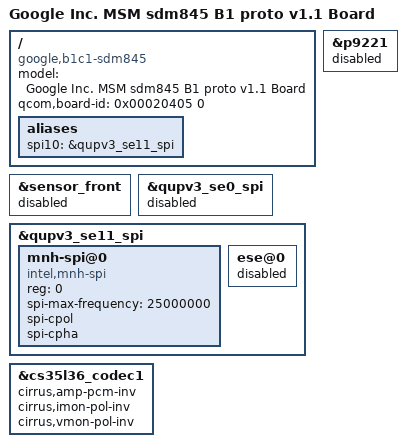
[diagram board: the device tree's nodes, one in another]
/* Copyright (c) 2017, The Linux Foundation. All rights reserved.
 *
 * This program is free software; you can redistribute it and/or modify
 * it under the terms of the GNU General Public License version 2 and
 * only version 2 as published by the Free Software Foundation.
 *
 * This program is distributed in the hope that it will be useful,
 * but WITHOUT ANY WARRANTY; without even the implied warranty of
 * MERCHANTABILITY or FITNESS FOR A PARTICULAR PURPOSE.  See the
 * GNU General Public License for more details.
 */


/dts-v1/;

#include "sdm845-b1-common-v2.dtsi"

/ {
	model = "Google Inc. MSM sdm845 B1 proto v1.1 Board";
	compatible = "google,b1c1-sdm845", "qcom,sdm845";
	qcom,board-id = <0x00020405 0>;
};

/* Workaround: Disable front normal camera, which has some MIPI issue. */
&sensor_front {
	status = "disabled";
};

/* B1 P1 has easel spi connected to se11 */
/ {
	aliases {
		spi10 = &qupv3_se11_spi;
	};
};
&qupv3_se0_spi {
	status = "disabled";
};
&qupv3_se11_spi {
	status = "okay";
	mnh-spi@0 {
		compatible = "intel,mnh-spi";
		reg = <0>;
		spi-max-frequency = <25000000>;
		spi-cpol;
		spi-cpha;
	};
	ese@0 {
		status = "disabled";
	};
};

#include "sdm845-b1c1-haptics-drv2624-overlay.dtsi"

/* B1 P1.1 has the bottom speaker amp in inverted polarity */
&cs35l36_codec1 {
	cirrus,amp-pcm-inv;
	cirrus,imon-pol-inv;
	cirrus,vmon-pol-inv;
};

/* Disable wchg on I2C10 */
&p9221 {
	status = "disabled";
};
